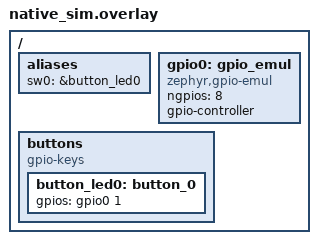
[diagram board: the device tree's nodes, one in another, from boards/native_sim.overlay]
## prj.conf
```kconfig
CONFIG_GPIO_EMUL=y
CONFIG_GPIO=y
CONFIG_LOG=y
CONFIG_EMUL=y
```

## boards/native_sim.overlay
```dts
#include <zephyr/dt-bindings/input/input-event-codes.h>

/ {
       aliases {
               sw0 = &button_led0;
       };
       gpio0: gpio_emul {
              compatible = "zephyr,gpio-emul";
              #gpio-cells = <2>;
              ngpios = <8>;
              gpio-controller;

        };
       buttons {
               compatible = "gpio-keys";
               button_led0: button_0 {
                       gpios = <&gpio0 1  GPIO_ACTIVE_HIGH>;
               };
       };
};
```

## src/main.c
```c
/*******************************************************************
 * @file main.c
 *
 * @brief Main file.
 * @author João Matheus Nascimento Dias (jmnd@ic.ufal.br)
 * @author José Félix de Oliveira Neto (jfon@ic.ufal.br)
 * @version 0.1
 * @date 26/08/2026
 *******************************************************************/

#include <errno.h>
#include <zephyr/drivers/gpio/gpio_emul.h>
#include <zephyr/logging/log.h>
#include <zephyr/sys/printk.h>

#include "board_io.h"

LOG_MODULE_REGISTER(main, LOG_LEVEL_ERR);

#define LED_BUTTON DT_ALIAS(sw0)
#define LED0_NODE  DT_ALIAS(led0)

static const struct gpio_dt_spec button = GPIO_DT_SPEC_GET(LED_BUTTON, gpios);
static const struct gpio_dt_spec led = GPIO_DT_SPEC_GET(LED0_NODE, gpios);

int main(void)
{

	if (io_init() < 0) {

		LOG_ERR("Error running io_init\n");
		return -errno;
	}

	for (int i = 0; i < 4; i++) {
		int button_value = button_read();
		int led_value = gpio_emul_output_get_dt(&led);

		printk("Button: %d -> LED: %d\n", button_value, led_value);
		gpio_emul_input_set(button.port, button.pin, !button_value);
		k_msleep(200);
		led_set(button_read());
	}
	return 0;
}
```

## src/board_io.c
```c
#include "board_io.h"

#include <errno.h>
#include <zephyr/drivers/gpio.h>
#include <zephyr/kernel.h>
#include <zephyr/logging/log.h>
#include <zephyr/sys/printk.h>

#define LED_BUTTON DT_ALIAS(sw0)
#define LED0_NODE  DT_ALIAS(led0)

static const struct gpio_dt_spec button = GPIO_DT_SPEC_GET(LED_BUTTON, gpios);
static const struct gpio_dt_spec led = GPIO_DT_SPEC_GET(LED0_NODE, gpios);

LOG_MODULE_REGISTER(board_io, LOG_LEVEL_ERR);

int io_init(void)
{

	if (!gpio_is_ready_dt(&led)) {

		LOG_ERR("Led gpio not ready\n");
		return -errno;
	}

	if (!gpio_is_ready_dt(&button)) {

		LOG_ERR("Button gpio not ready\n");
		return -errno;
	}

	if (gpio_pin_configure_dt(&led, GPIO_OUTPUT_LOW) < 0) {

		LOG_ERR("Unable to set led pin as output\n");
		return -errno;
	}

	if (gpio_pin_configure_dt(&button, GPIO_INPUT) < 0) {

		LOG_ERR("Unable to set button pin as input\n");
		return -errno;
	}

	return 0;
}

int led_set(bool on)
{
	if (gpio_pin_set_dt(&led, on) < 0) {

		LOG_ERR("Unable to set led pin state\n");
		return -errno;
	}
	return 0;
}

int button_read(void)
{
	int button_state = gpio_pin_get_dt(&button);
	if (button_state < 0) {

		LOG_ERR("Unable to get button pin state\n");
		return -1;
	}
	return button_state;
}
```

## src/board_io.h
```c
/*******************************************************************
 * @file board_io.h
 *
 * @brief Interface do módulo de entradas/saídas (Atividade-03).
 *******************************************************************/

#ifndef BOARD_IO_H_
#define BOARD_IO_H_

#include <stdbool.h>

#include <zephyr/devicetree.h>
#include <zephyr/drivers/gpio.h>
#include <zephyr/kernel.h>
/* O native_sim só declara o LED (alias led0). O botão (alias sw0) precisa
 * vir de um overlay de devicetree criado por você. */
#if !DT_NODE_EXISTS(DT_ALIAS(sw0))
#error "Alias sw0 nao existe: crie um overlay de devicetree descrevendo o botao."
#endif

/* Configura LED (saída, iniciando desligado) e botão (entrada), obtidos do
 * devicetree pelos aliases led0 e sw0. Retorna 0 ou errno negativo. */
int io_init(void);

/* Escreve o nível lógico do LED (ativo em alto). Retorna 0 ou errno negativo. */
int led_set(bool on);

/* Lê o botão: 1 pressionado, 0 solto, ou errno negativo. */
int button_read(void);

#endif /* BOARD_IO_H_ */
```
